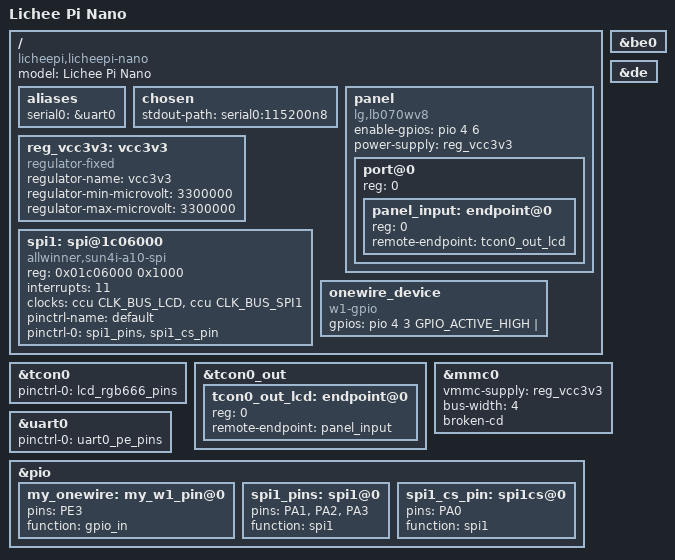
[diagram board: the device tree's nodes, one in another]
// SPDX-License-Identifier: (GPL-2.0+ OR X11)
/*
 * Copyright 2018 Icenowy Zheng <icenowy@aosc.io>
 */

/dts-v1/;
#include "suniv-f1c100s.dtsi"
#include <dt-bindings/gpio/gpio.h>

/ {
	model = "Lichee Pi Nano";
	compatible = "licheepi,licheepi-nano", "allwinner,suniv-f1c100s";

	aliases {
		serial0 = &uart0;
	};

	chosen {
		stdout-path = "serial0:115200n8";
	};

	panel: panel {
		compatible = "lg,lb070wv8", "simple-panel";
		#address-cells = <1>;
		#size-cells = <0>;
		enable-gpios = <&pio 4 6 GPIO_ACTIVE_HIGH>;
		power-supply = <&reg_vcc3v3>;

 		port@0 {
			reg = <0>;
			#address-cells = <1>;
			#size-cells = <0>;

 			panel_input: endpoint@0 {
				reg = <0>;
				remote-endpoint = <&tcon0_out_lcd>;
			};
		};
	};

	reg_vcc3v3: vcc3v3 {
		compatible = "regulator-fixed";
		regulator-name = "vcc3v3";
		regulator-min-microvolt = <3300000>;
		regulator-max-microvolt = <3300000>;
	};

	spi1: spi@1c06000 {
		compatible = "allwinner,sun4i-a10-spi";
		reg = <0x01c06000 0x1000>;
		interrupts = <11>;
		//todo: clocks
		clocks = <&ccu CLK_BUS_LCD>, <&ccu CLK_BUS_SPI1>;
		clock-names = "ahb", "mod";
		#address-cells = <1>;
		#size-cells = <0>;
		status = "okay";
		pinctrl-name = "default";
		pinctrl-0 = <&spi1_pins>, <&spi1_cs_pin>;
	};

	onewire_device {
		compatible = "w1-gpio";
		gpios = <&pio 4 3 GPIO_ACTIVE_HIGH | GPIO_PULL_UP>;
		pinctrl-names = "default";
		//pinctrl-0 = <&my_onewire>;
	};
};

&be0 {
	status = "okay";
};

&de {
	status = "okay";
};

&tcon0 {
	pinctrl-names = "default";
	pinctrl-0 = <&lcd_rgb666_pins>;
	status = "okay";
};

&tcon0_out {
	tcon0_out_lcd: endpoint@0 {
		reg = <0>;
		remote-endpoint = <&panel_input>;
	};
};

&mmc0 {
	vmmc-supply = <&reg_vcc3v3>;
	bus-width = <4>;
	broken-cd;
	status = "okay";
};

&uart0 {
	pinctrl-names = "default";
	pinctrl-0 = <&uart0_pe_pins>;
	status = "okay";
};

&pio {
	my_onewire: my_w1_pin@0 {
		pins = "PE3";
		function = "gpio_in";
	};

	spi1_pins: spi1@0 {
		pins = "PA1", "PA2", "PA3";
		function = "spi1";
	};

	spi1_cs_pin: spi1cs@0 {
		pins = "PA0";
		function = "spi1";
	};
};
